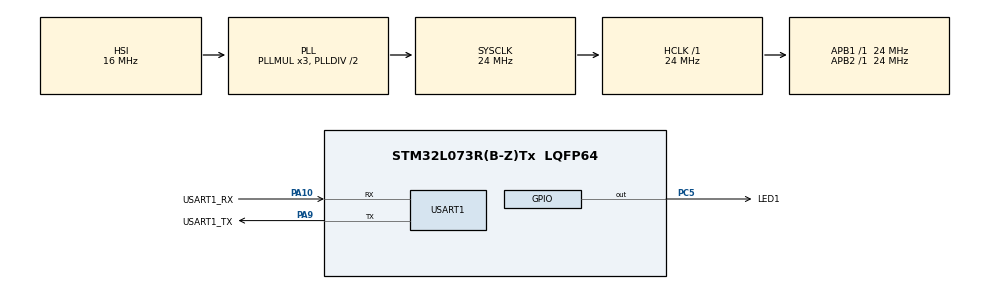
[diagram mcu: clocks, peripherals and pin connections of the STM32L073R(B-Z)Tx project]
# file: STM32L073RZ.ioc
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Mcu.Family=STM32L0
Mcu.Name=STM32L073R(B-Z)Tx
Mcu.Package=LQFP64
PA10.GPIO_Label=USART1_RX
PA10.Mode=Asynchronous
PA10.Signal=USART1_RX
PA9.GPIO_Label=USART1_TX
PA9.Mode=Asynchronous
PA9.Signal=USART1_TX
PC14-OSC32_IN.Mode=LSE-External-Oscillator
PC14-OSC32_IN.Signal=RCC_OSC32_IN
PC15-OSC32_OUT.Mode=LSE-External-Oscillator
PC15-OSC32_OUT.Signal=RCC_OSC32_OUT
PC5.GPIO_Label=LED1
PC5.Signal=GPIO_Output
ProjectManager.HeapSize=0x200
ProjectManager.StackSize=0x400
ProjectManager.TargetToolchain=MDK-ARM V5
RCC.ADCFreq_Value=16000000
RCC.AHBFreq_Value=24000000
RCC.APB1Freq_Value=24000000
RCC.APB1TimFreq_Value=24000000
RCC.APB2Freq_Value=24000000
RCC.APB2TimFreq_Value=24000000
RCC.HCLKFreq_Value=24000000
RCC.HSE_VALUE=8000000
RCC.HSI16_VALUE=16000000
RCC.HSI48_VALUE=48000000
RCC.HSI_VALUE=16000000
RCC.MSI_VALUE=2097000
RCC.SYSCLKFreq_VALUE=24000000
RCC.SYSCLKSource=RCC_SYSCLKSOURCE_PLLCLK
RCC.VCOOutputFreq_Value=48000000
USART1.VirtualMode-Asynchronous=VM_ASYNC
VP_CRC_VS_CRC.Mode=CRC_Activate
board=custom

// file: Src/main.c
/**
  ******************************************************************************
  * @file           : main.c
  * @brief          : Main program body
  ******************************************************************************
  ** This notice applies to any and all portions of this file
  * that are not between comment pairs USER CODE BEGIN and
  * USER CODE END. Other portions of this file, whether
  * inserted by the user or by software development tools
  * are owned by their respective copyright owners.
  *
  * COPYRIGHT(c) 2018 STMicroelectronics
  *
  * Redistribution and use in source and binary forms, with or without modification,
  * are permitted provided that the following conditions are met:
  *   1. Redistributions of source code must retain the above copyright notice,
  *      this list of conditions and the following disclaimer.
  *   2. Redistributions in binary form must reproduce the above copyright notice,
  *      this list of conditions and the following disclaimer in the documentation
  *      and/or other materials provided with the distribution.
  *   3. Neither the name of STMicroelectronics nor the names of its contributors
  *      may be used to endorse or promote products derived from this software
  *      without specific prior written permission.
  *
  * THIS SOFTWARE IS PROVIDED BY THE COPYRIGHT HOLDERS AND CONTRIBUTORS "AS IS"
  * AND ANY EXPRESS OR IMPLIED WARRANTIES, INCLUDING, BUT NOT LIMITED TO, THE
  * IMPLIED WARRANTIES OF MERCHANTABILITY AND FITNESS FOR A PARTICULAR PURPOSE ARE
  * DISCLAIMED. IN NO EVENT SHALL THE COPYRIGHT HOLDER OR CONTRIBUTORS BE LIABLE
  * FOR ANY DIRECT, INDIRECT, INCIDENTAL, SPECIAL, EXEMPLARY, OR CONSEQUENTIAL
  * DAMAGES (INCLUDING, BUT NOT LIMITED TO, PROCUREMENT OF SUBSTITUTE GOODS OR
  * SERVICES; LOSS OF USE, DATA, OR PROFITS; OR BUSINESS INTERRUPTION) HOWEVER
  * CAUSED AND ON ANY THEORY OF LIABILITY, WHETHER IN CONTRACT, STRICT LIABILITY,
  * OR TORT (INCLUDING NEGLIGENCE OR OTHERWISE) ARISING IN ANY WAY OUT OF THE USE
  * OF THIS SOFTWARE, EVEN IF ADVISED OF THE POSSIBILITY OF SUCH DAMAGE.
  *
  ******************************************************************************
  */
#include "main.h"
#include "stm32l0xx_hal.h"
#include "crc.h"
#include "usart.h"
#include "gpio.h"
#include "common.h"
#include "flash_if.h"
#include "menu.h"

/* USER CODE BEGIN PV */
/* Private variables ---------------------------------------------------------*/

/* USER CODE END PV */

void SystemClock_Config(void);

/* USER CODE BEGIN PFP */
/* Private function prototypes -----------------------------------------------*/

/* USER CODE END PFP */

/* USER CODE BEGIN 0 */
//---------------------------------IAP------------------------------------------
typedef   void (*pFunction)(void);
pFunction JumpToApplication;
uint32_t JumpAddress;

//set flasj run flag
void SetFalshRun_Flag(uint32_t FlashFlag)
{
  FLASH_EraseInitTypeDef EraseInitStruct;
	uint32_t PAGEError = 0;
	uint32_t Data;

	Data = FlashFlag;

	HAL_FLASH_Unlock();
	EraseInitStruct.TypeErase   = FLASH_TYPEERASE_PAGES;
	EraseInitStruct.PageAddress = IAP_FLASH_MARKADDESS;
	EraseInitStruct.NbPages     = 1;

	if (HAL_FLASHEx_Erase(&EraseInitStruct, &PAGEError) != HAL_OK)  //erase 1 page (256byte)
	{
		Serial_PutString((uint8_t *)"FLASH Erase Fail...\r\n");
	}

	if (HAL_FLASH_Program(FLASH_TYPEPROGRAM_WORD, IAP_FLASH_MARKADDESS, Data) != HAL_OK)
	{
		Serial_PutString((uint8_t *)"FLASH Write Fail...\r\n");
	}

	HAL_FLASH_Lock();
}

//Jump app addess
void Iap_Load_App(void)
{
	/* Test if user code is programmed starting from address "APPLICATION_ADDRESS" */
	if (((*(__IO uint32_t*)APPLICATION_ADDRESS) & 0x2FFE0000 ) == 0x20000000)
	{
		/* Jump to user application */
		JumpAddress = *(__IO uint32_t*) (APPLICATION_ADDRESS + 4);
		JumpToApplication = (pFunction) JumpAddress;
		/* Initialize user application's Stack Pointer */
		__set_MSP(*(__IO uint32_t*) APPLICATION_ADDRESS);
		JumpToApplication();
	}
}

//-------------------------------------End-----------------------------------
/* USER CODE END 0 */

int main(void)
{

  /* MCU Configuration----------------------------------------------------------*/

  /* Reset of all peripherals, Initializes the Flash interface and the Systick. */
  HAL_Init();

  /* Configure the system clock */
  SystemClock_Config();

  /* Initialize all configured peripherals */
  MX_GPIO_Init();
  MX_CRC_Init();
	FLASH_If_Init();
	MX_USART1_UART_Init();

  /* USER CODE BEGIN 2 */

	if ((*(__IO uint32_t *)IAP_FLASH_MARKADDESS) == RUN_DOWNLOAD_FLAG || (*(__IO uint32_t *)IAP_FLASH_MARKADDESS) == RUN_UPLOAD_FLAG ||
			(*(__IO uint32_t *)IAP_FLASH_MARKADDESS) == FOTA_DOWNLOAD_FLAG)
  {
			Serial_PutString((uint8_t *)"bootloader\r\n");
			HAL_GPIO_WritePin(LED1_GPIO_Port, LED1_Pin, GPIO_PIN_SET);

			if ((*(__IO uint32_t *)IAP_FLASH_MARKADDESS) == FOTA_DOWNLOAD_FLAG)
			{
					FLASH_If_Erase(APPLICATION_ADDRESS, FLASH_APP_RUNUING_END);
					FLASH_IF_COPY((uint32_t*)FLASH_APP_BACKUP_START, APPLICATION_ADDRESS, USER_APP_SIZE);
					SetFalshRun_Flag(RUN_APP_FLAG);
					HAL_Delay(100);
					Iap_Load_App();
			}
			else
			{
					Main_Menu();
			}
  }
  else
  {
			Serial_PutString((uint8_t *)"application\r\n");
			if((*(__IO uint32_t *)IAP_FLASH_MARKADDESS) == UPDATA_APP_FAILED_FLAG)
			{
					FLASH_If_Erase(APPLICATION_ADDRESS, FLASH_APP_RUNUING_END);
					FLASH_IF_COPY((uint32_t*)FLASH_APP_BACKUP_START, APPLICATION_ADDRESS, USER_APP_SIZE);
					SetFalshRun_Flag(RUN_APP_FLAG);
			}

			Iap_Load_App(); /* Keep the user application running */
  }
  /* USER CODE END 2 */

  /* Infinite loop */
  while (1)
  {
  }

}

void SystemClock_Config(void)
{
  RCC_OscInitTypeDef RCC_OscInitStruct;
  RCC_ClkInitTypeDef RCC_ClkInitStruct;
  RCC_PeriphCLKInitTypeDef PeriphClkInit;

  /**Configure the main internal regulator output voltage */
  __HAL_PWR_VOLTAGESCALING_CONFIG(PWR_REGULATOR_VOLTAGE_SCALE1);

  /**Initializes the CPU, AHB and APB busses clocks */
  RCC_OscInitStruct.OscillatorType = RCC_OSCILLATORTYPE_HSI;
  RCC_OscInitStruct.HSIState = RCC_HSI_ON;
  RCC_OscInitStruct.HSICalibrationValue = 16;
  RCC_OscInitStruct.PLL.PLLState = RCC_PLL_ON;
  RCC_OscInitStruct.PLL.PLLSource = RCC_PLLSOURCE_HSI;
  RCC_OscInitStruct.PLL.PLLMUL = RCC_PLLMUL_3;
  RCC_OscInitStruct.PLL.PLLDIV = RCC_PLLDIV_2;
  if (HAL_RCC_OscConfig(&RCC_OscInitStruct) != HAL_OK)
  {
    _Error_Handler(__FILE__, __LINE__);
  }

  /**Initializes the CPU, AHB and APB busses clocks */
  RCC_ClkInitStruct.ClockType = RCC_CLOCKTYPE_HCLK|RCC_CLOCKTYPE_SYSCLK
                              |RCC_CLOCKTYPE_PCLK1|RCC_CLOCKTYPE_PCLK2;
  RCC_ClkInitStruct.SYSCLKSource = RCC_SYSCLKSOURCE_PLLCLK;
  RCC_ClkInitStruct.AHBCLKDivider = RCC_SYSCLK_DIV1;
  RCC_ClkInitStruct.APB1CLKDivider = RCC_HCLK_DIV1;
  RCC_ClkInitStruct.APB2CLKDivider = RCC_HCLK_DIV1;

  if (HAL_RCC_ClockConfig(&RCC_ClkInitStruct, FLASH_LATENCY_1) != HAL_OK)
  {
    _Error_Handler(__FILE__, __LINE__);
  }

  PeriphClkInit.PeriphClockSelection = RCC_PERIPHCLK_USART1;
  PeriphClkInit.Usart1ClockSelection = RCC_USART1CLKSOURCE_PCLK2;
  if (HAL_RCCEx_PeriphCLKConfig(&PeriphClkInit) != HAL_OK)
  {
    _Error_Handler(__FILE__, __LINE__);
  }

  /**Configure the Systick interrupt time */
  HAL_SYSTICK_Config(HAL_RCC_GetHCLKFreq()/1000);

  /**Configure the Systick */
  HAL_SYSTICK_CLKSourceConfig(SYSTICK_CLKSOURCE_HCLK);

  /* SysTick_IRQn interrupt configuration */
  HAL_NVIC_SetPriority(SysTick_IRQn, 0, 0);
}

void _Error_Handler(char *file, int line)
{
  while(1)
  {
  }
}

/************************ (C) COPYRIGHT STMicroelectronics *****END OF FILE****/
